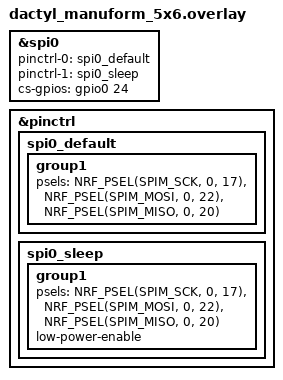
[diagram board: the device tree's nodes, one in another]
/* https://forum.seeedstudio.com/t/xiao-nrf52840-plus/294262/7
*/

nice_view_spi: &spi0 { };

&pinctrl {
    spi0_default: spi0_default {
        group1 {
            psels = <NRF_PSEL(SPIM_SCK, 0, 17)>,  /* P0.17 */
                    <NRF_PSEL(SPIM_MOSI, 0, 22)>, /* P0.22 */
                    <NRF_PSEL(SPIM_MISO, 0, 20)>; /* P0.20 */
        };
    };

    spi0_sleep: spi0_sleep {
        group1 {
            psels = <NRF_PSEL(SPIM_SCK, 0, 17)>,
                    <NRF_PSEL(SPIM_MOSI, 0, 22)>,
                    <NRF_PSEL(SPIM_MISO, 0, 20)>;
            low-power-enable;
        };
    };
};

&spi0 {
    status = "okay";
    pinctrl-0 = <&spi0_default>;
    pinctrl-1 = <&spi0_sleep>;
    pinctrl-names = "default", "sleep";
    
    /* Chip Select on P0.24 */
    cs-gpios = <&gpio0 24 GPIO_ACTIVE_HIGH>;
};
